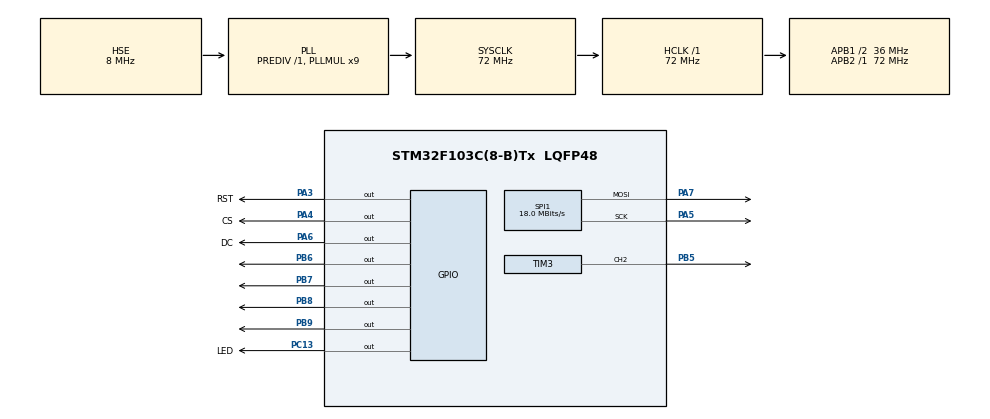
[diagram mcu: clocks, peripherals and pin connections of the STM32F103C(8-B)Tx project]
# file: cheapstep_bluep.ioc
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Mcu.Family=STM32F1
Mcu.Name=STM32F103C(8-B)Tx
Mcu.Package=LQFP48
NVIC.PriorityGroup=NVIC_PRIORITYGROUP_4
PA13.Mode=Trace_Asynchronous_SW
PA13.Signal=SYS_JTMS-SWDIO
PA14.Mode=Trace_Asynchronous_SW
PA14.Signal=SYS_JTCK-SWCLK
PA3.GPIO_Label=RST
PA3.Signal=GPIO_Output
PA4.GPIO_Label=CS
PA4.Signal=GPIO_Output
PA5.Mode=TX_Only_Simplex_Unidirect_Master
PA5.Signal=SPI1_SCK
PA6.GPIO_Label=DC
PA6.Signal=GPIO_Output
PA7.Mode=TX_Only_Simplex_Unidirect_Master
PA7.Signal=SPI1_MOSI
PB3.Mode=Trace_Asynchronous_SW
PB3.Signal=SYS_JTDO-TRACESWO
PB5.Signal=S_TIM3_CH2
PB6.Signal=GPIO_Output
PB7.Signal=GPIO_Output
PB8.Signal=GPIO_Output
PB9.Signal=GPIO_Output
PC13-TAMPER-RTC.GPIO_Label=LED
PC13-TAMPER-RTC.Signal=GPIO_Output
PD0-OSC_IN.Mode=HSE-External-Oscillator
PD0-OSC_IN.Signal=RCC_OSC_IN
PD1-OSC_OUT.Mode=HSE-External-Oscillator
PD1-OSC_OUT.Signal=RCC_OSC_OUT
ProjectManager.HeapSize=0x200
ProjectManager.StackSize=0x400
ProjectManager.TargetToolchain=STM32CubeIDE
RCC.AHBFreq_Value=72000000
RCC.APB1CLKDivider=RCC_HCLK_DIV2
RCC.APB1Freq_Value=36000000
RCC.APB1TimFreq_Value=72000000
RCC.APB2Freq_Value=72000000
RCC.APB2TimFreq_Value=72000000
RCC.HCLKFreq_Value=72000000
RCC.PLLMUL=RCC_PLL_MUL9
RCC.PLLSourceVirtual=RCC_PLLSOURCE_HSE
RCC.SYSCLKFreq_VALUE=72000000
RCC.SYSCLKSource=RCC_SYSCLKSOURCE_PLLCLK
RCC.USBFreq_Value=72000000
SH.S_TIM3_CH2.0=TIM3_CH2,PWM Generation2 CH2
SPI1.BaudRatePrescaler=SPI_BAUDRATEPRESCALER_4
SPI1.CalculateBaudRate=18.0 MBits/s
SPI1.Direction=SPI_DIRECTION_2LINES
SPI1.Mode=SPI_MODE_MASTER
SPI1.VirtualType=VM_MASTER
TIM3.Channel-PWM\ Generation2\ CH2=TIM_CHANNEL_2
TIM4.Prescaler=100
VP_TIM4_VS_ClockSourceINT.Mode=Internal
board=custom

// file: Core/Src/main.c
/* USER CODE BEGIN Header */
/**
 ******************************************************************************
 * @file           : main.c
 * @brief          : Main program body
 ******************************************************************************
 * @attention
 *
 * Copyright (c) 2024 STMicroelectronics.
 * All rights reserved.
 *
 * This software is licensed under terms that can be found in the LICENSE file
 * in the root directory of this software component.
 * If no LICENSE file comes with this software, it is provided AS-IS.
 *
 ******************************************************************************
 */
/*
https://lastminuteengineers.com/28byj48-stepper-motor-arduino-tutorial/
32 steps/rotation x64 reducer = 2048 full steps in one rev
*/

/* USER CODE END Header */
#include "main.h"

SPI_HandleTypeDef hspi1;

TIM_HandleTypeDef htim3;
TIM_HandleTypeDef htim4;

void SystemClock_Config(void);
static void MX_GPIO_Init(void);
static void MX_TIM4_Init(void);
static void MX_TIM3_Init(void);
static void MX_SPI1_Init(void);

/* USER CODE BEGIN 0 */

void LCD_1in9_test(void);

/*
#define frt_timer	(htim4)
void frt_start(void) {
	frt_timer.Instance->CNT = 0;
	__HAL_TIM_ENABLE(&frt_timer);
}

uint16_t frt_stop(void) {
	__HAL_TIM_DISABLE(&frt_timer);
	return frt_timer.Instance->CNT;
}

void frt_wait_ns(uint16_t tick) {
	frt_timer.Instance->CNT = 0;
	__HAL_TIM_ENABLE(&frt_timer);
	while (frt_timer.Instance->CNT < tick) ;
	__HAL_TIM_DISABLE(&frt_timer);
}
*/

/*volatile int n0=1,n1=2,n2=3,n3=0;
volatile int delay=6000, steps=0;

volatile int min_delay=600;
volatile int speed=0;
volatile int acc = 0;*/

/* USER CODE END 0 */

int main(void)
{

  /* MCU Configuration--------------------------------------------------------*/

  /* Reset of all peripherals, Initializes the Flash interface and the Systick. */
  HAL_Init();

  /* Configure the system clock */
  SystemClock_Config();

  /* Initialize all configured peripherals */
  MX_GPIO_Init();
  MX_TIM4_Init();
  MX_TIM3_Init();
  MX_SPI1_Init();

  /* Infinite loop */
  /* USER CODE BEGIN WHILE */
 	//int state = 0;
/*
 	HAL_GPIO_WritePin(GPIOB, GPIO_PIN_6, 0);
	HAL_GPIO_WritePin(GPIOB, GPIO_PIN_7, 0);
	HAL_GPIO_WritePin(GPIOB, GPIO_PIN_8, 0);
	HAL_GPIO_WritePin(GPIOB, GPIO_PIN_9, 0);*/

	while (1) {
    /* USER CODE END WHILE */

    /* USER CODE BEGIN 3 */
		LCD_1in9_test();

		HAL_GPIO_TogglePin(LED_GPIO_Port, LED_Pin);
		//HAL_Delay(delay);
	/*	frt_wait_ns(delay);
		steps++;

		if(delay>min_delay){
			acc++;
			speed+=acc;
			delay-=speed>>4;
		}

		switch (state) {
		case 0:
			HAL_GPIO_WritePin(GPIOB, GPIO_PIN_6, 0);
			HAL_GPIO_WritePin(GPIOB, GPIO_PIN_9, 1);
			state = n0;
			break;
		case 1:
			HAL_GPIO_WritePin(GPIOB, GPIO_PIN_9, 0);
			HAL_GPIO_WritePin(GPIOB, GPIO_PIN_8, 1);
			state = n1;
			break;
		case 2:
			HAL_GPIO_WritePin(GPIOB, GPIO_PIN_8, 0);
			HAL_GPIO_WritePin(GPIOB, GPIO_PIN_7, 1);
			state = n2;
			break;
		case 3:
			HAL_GPIO_WritePin(GPIOB, GPIO_PIN_7, 0);
			HAL_GPIO_WritePin(GPIOB, GPIO_PIN_6, 1);
			state = n3;
			break;
		default: state = 0;
		}*/

	}
  /* USER CODE END 3 */
}

void SystemClock_Config(void)
{
  RCC_OscInitTypeDef RCC_OscInitStruct = {0};
  RCC_ClkInitTypeDef RCC_ClkInitStruct = {0};

  /** Initializes the RCC Oscillators according to the specified parameters
  * in the RCC_OscInitTypeDef structure.
  */
  RCC_OscInitStruct.OscillatorType = RCC_OSCILLATORTYPE_HSE;
  RCC_OscInitStruct.HSEState = RCC_HSE_ON;
  RCC_OscInitStruct.HSEPredivValue = RCC_HSE_PREDIV_DIV1;
  RCC_OscInitStruct.HSIState = RCC_HSI_ON;
  RCC_OscInitStruct.PLL.PLLState = RCC_PLL_ON;
  RCC_OscInitStruct.PLL.PLLSource = RCC_PLLSOURCE_HSE;
  RCC_OscInitStruct.PLL.PLLMUL = RCC_PLL_MUL9;
  if (HAL_RCC_OscConfig(&RCC_OscInitStruct) != HAL_OK)
  {
    Error_Handler();
  }

  /** Initializes the CPU, AHB and APB buses clocks
  */
  RCC_ClkInitStruct.ClockType = RCC_CLOCKTYPE_HCLK|RCC_CLOCKTYPE_SYSCLK
                              |RCC_CLOCKTYPE_PCLK1|RCC_CLOCKTYPE_PCLK2;
  RCC_ClkInitStruct.SYSCLKSource = RCC_SYSCLKSOURCE_PLLCLK;
  RCC_ClkInitStruct.AHBCLKDivider = RCC_SYSCLK_DIV1;
  RCC_ClkInitStruct.APB1CLKDivider = RCC_HCLK_DIV2;
  RCC_ClkInitStruct.APB2CLKDivider = RCC_HCLK_DIV1;

  if (HAL_RCC_ClockConfig(&RCC_ClkInitStruct, FLASH_LATENCY_2) != HAL_OK)
  {
    Error_Handler();
  }
}

static void MX_SPI1_Init(void)
{

  /* SPI1 parameter configuration*/
  hspi1.Instance = SPI1;
  hspi1.Init.Mode = SPI_MODE_MASTER;
  hspi1.Init.Direction = SPI_DIRECTION_2LINES;
  hspi1.Init.DataSize = SPI_DATASIZE_8BIT;
  hspi1.Init.CLKPolarity = SPI_POLARITY_LOW;
  hspi1.Init.CLKPhase = SPI_PHASE_1EDGE;
  hspi1.Init.NSS = SPI_NSS_SOFT;
  hspi1.Init.BaudRatePrescaler = SPI_BAUDRATEPRESCALER_4;
  hspi1.Init.FirstBit = SPI_FIRSTBIT_MSB;
  hspi1.Init.TIMode = SPI_TIMODE_DISABLE;
  hspi1.Init.CRCCalculation = SPI_CRCCALCULATION_DISABLE;
  hspi1.Init.CRCPolynomial = 10;
  if (HAL_SPI_Init(&hspi1) != HAL_OK)
  {
    Error_Handler();
  }

}

static void MX_TIM3_Init(void)
{

  TIM_MasterConfigTypeDef sMasterConfig = {0};
  TIM_OC_InitTypeDef sConfigOC = {0};

  htim3.Instance = TIM3;
  htim3.Init.Prescaler = 0;
  htim3.Init.CounterMode = TIM_COUNTERMODE_UP;
  htim3.Init.Period = 65535;
  htim3.Init.ClockDivision = TIM_CLOCKDIVISION_DIV1;
  htim3.Init.AutoReloadPreload = TIM_AUTORELOAD_PRELOAD_DISABLE;
  if (HAL_TIM_PWM_Init(&htim3) != HAL_OK)
  {
    Error_Handler();
  }
  sMasterConfig.MasterOutputTrigger = TIM_TRGO_RESET;
  sMasterConfig.MasterSlaveMode = TIM_MASTERSLAVEMODE_DISABLE;
  if (HAL_TIMEx_MasterConfigSynchronization(&htim3, &sMasterConfig) != HAL_OK)
  {
    Error_Handler();
  }
  sConfigOC.OCMode = TIM_OCMODE_PWM1;
  sConfigOC.Pulse = 0;
  sConfigOC.OCPolarity = TIM_OCPOLARITY_HIGH;
  sConfigOC.OCFastMode = TIM_OCFAST_DISABLE;
  if (HAL_TIM_PWM_ConfigChannel(&htim3, &sConfigOC, TIM_CHANNEL_2) != HAL_OK)
  {
    Error_Handler();
  }
  HAL_TIM_MspPostInit(&htim3);

}

static void MX_TIM4_Init(void)
{

  TIM_ClockConfigTypeDef sClockSourceConfig = {0};
  TIM_MasterConfigTypeDef sMasterConfig = {0};

  htim4.Instance = TIM4;
  htim4.Init.Prescaler = 100;
  htim4.Init.CounterMode = TIM_COUNTERMODE_UP;
  htim4.Init.Period = 65535;
  htim4.Init.ClockDivision = TIM_CLOCKDIVISION_DIV1;
  htim4.Init.AutoReloadPreload = TIM_AUTORELOAD_PRELOAD_DISABLE;
  if (HAL_TIM_Base_Init(&htim4) != HAL_OK)
  {
    Error_Handler();
  }
  sClockSourceConfig.ClockSource = TIM_CLOCKSOURCE_INTERNAL;
  if (HAL_TIM_ConfigClockSource(&htim4, &sClockSourceConfig) != HAL_OK)
  {
    Error_Handler();
  }
  sMasterConfig.MasterOutputTrigger = TIM_TRGO_RESET;
  sMasterConfig.MasterSlaveMode = TIM_MASTERSLAVEMODE_DISABLE;
  if (HAL_TIMEx_MasterConfigSynchronization(&htim4, &sMasterConfig) != HAL_OK)
  {
    Error_Handler();
  }

}

static void MX_GPIO_Init(void)
{
  GPIO_InitTypeDef GPIO_InitStruct = {0};

  /* GPIO Ports Clock Enable */
  __HAL_RCC_GPIOC_CLK_ENABLE();
  __HAL_RCC_GPIOD_CLK_ENABLE();
  __HAL_RCC_GPIOA_CLK_ENABLE();
  __HAL_RCC_GPIOB_CLK_ENABLE();

  /*Configure GPIO pin Output Level */
  HAL_GPIO_WritePin(LED_GPIO_Port, LED_Pin, GPIO_PIN_RESET);

  /*Configure GPIO pin Output Level */
  HAL_GPIO_WritePin(GPIOA, RST_Pin|CS_Pin|DC_Pin, GPIO_PIN_RESET);

  /*Configure GPIO pin Output Level */
  HAL_GPIO_WritePin(GPIOB, GPIO_PIN_6|GPIO_PIN_7|GPIO_PIN_8|GPIO_PIN_9, GPIO_PIN_RESET);

  /*Configure GPIO pin : LED_Pin */
  GPIO_InitStruct.Pin = LED_Pin;
  GPIO_InitStruct.Mode = GPIO_MODE_OUTPUT_PP;
  GPIO_InitStruct.Pull = GPIO_NOPULL;
  GPIO_InitStruct.Speed = GPIO_SPEED_FREQ_LOW;
  HAL_GPIO_Init(LED_GPIO_Port, &GPIO_InitStruct);

  /*Configure GPIO pins : RST_Pin CS_Pin DC_Pin */
  GPIO_InitStruct.Pin = RST_Pin|CS_Pin|DC_Pin;
  GPIO_InitStruct.Mode = GPIO_MODE_OUTPUT_PP;
  GPIO_InitStruct.Pull = GPIO_NOPULL;
  GPIO_InitStruct.Speed = GPIO_SPEED_FREQ_LOW;
  HAL_GPIO_Init(GPIOA, &GPIO_InitStruct);

  /*Configure GPIO pins : PB6 PB7 PB8 PB9 */
  GPIO_InitStruct.Pin = GPIO_PIN_6|GPIO_PIN_7|GPIO_PIN_8|GPIO_PIN_9;
  GPIO_InitStruct.Mode = GPIO_MODE_OUTPUT_PP;
  GPIO_InitStruct.Pull = GPIO_NOPULL;
  GPIO_InitStruct.Speed = GPIO_SPEED_FREQ_LOW;
  HAL_GPIO_Init(GPIOB, &GPIO_InitStruct);

}

void Error_Handler(void)
{
	__disable_irq();
	while (1) {
	}
}
